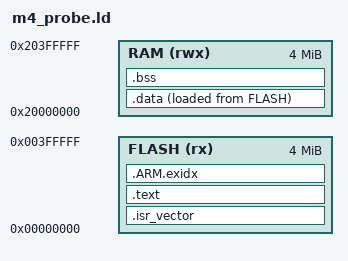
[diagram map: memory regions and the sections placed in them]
ENTRY(probe_reset)

MEMORY
{
  FLASH (rx) : ORIGIN = 0x00000000, LENGTH = 4M
  RAM (rwx) : ORIGIN = 0x20000000, LENGTH = 4M
}

SECTIONS
{
  .isr_vector : { KEEP(*(.isr_vector)) } > FLASH
  .text : { *(.text*) *(.rodata*) } > FLASH
  .ARM.exidx : { *(.ARM.exidx*) } > FLASH
  .data : { *(.data*) } > RAM AT > FLASH
  .bss (NOLOAD) : { *(.bss*) *(COMMON) } > RAM
}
